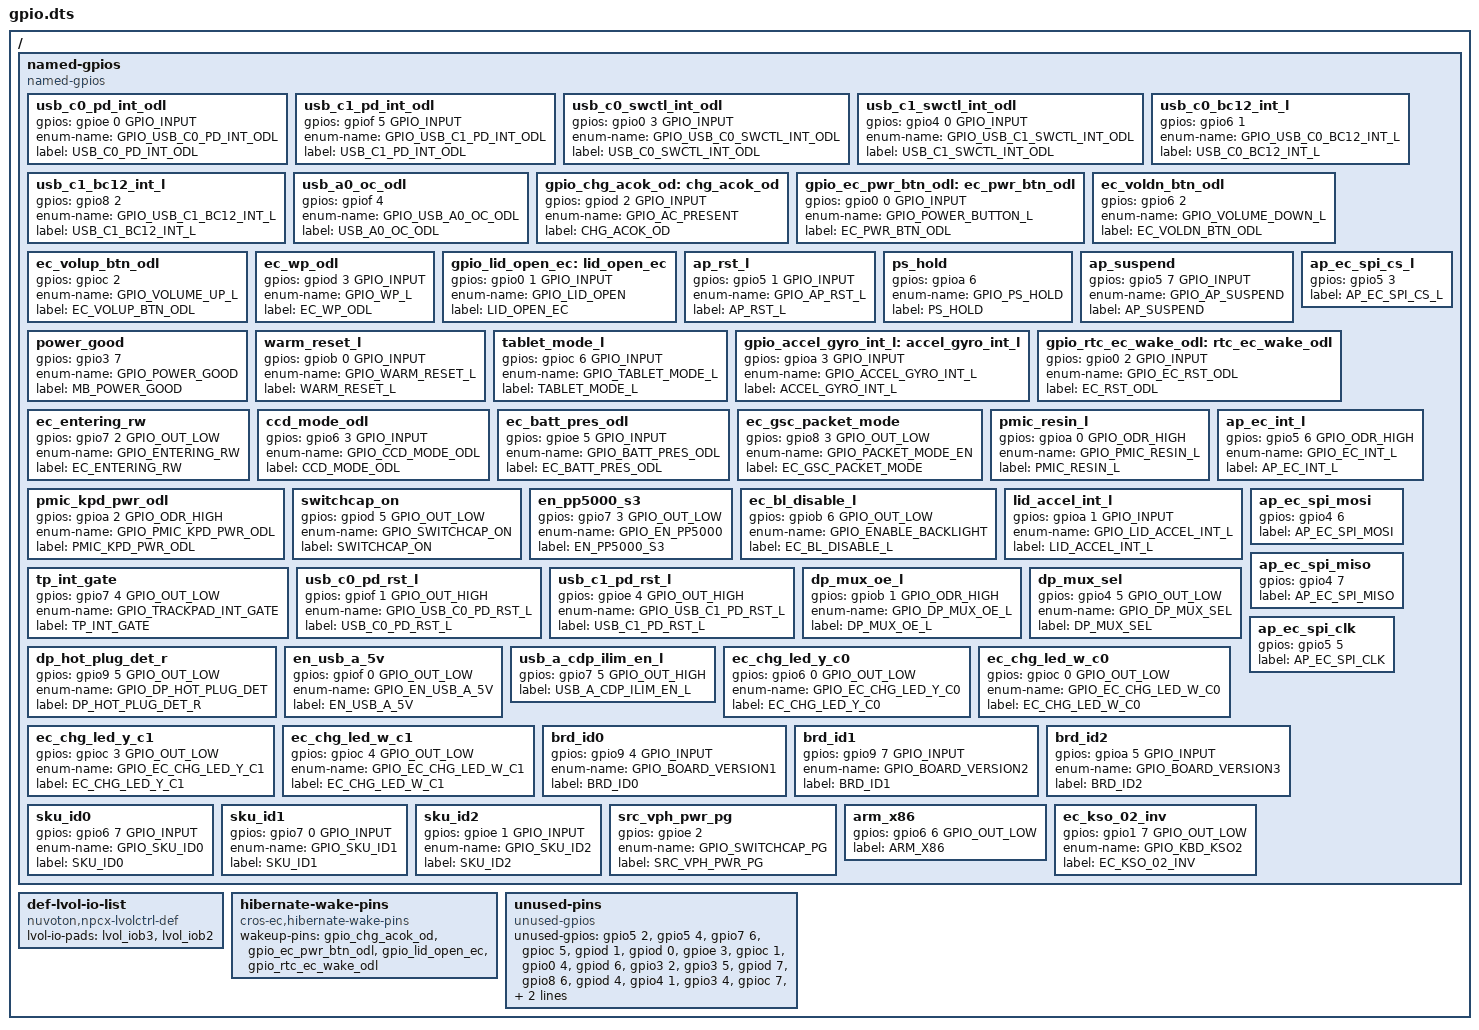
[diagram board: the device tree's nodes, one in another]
/* Copyright 2021 The Chromium OS Authors. All rights reserved.
 * Use of this source code is governed by a BSD-style license that can be
 * found in the LICENSE file.
 */

/ {
	named-gpios {
		compatible = "named-gpios";

		usb_c0_pd_int_odl {
			gpios = <&gpioe 0 GPIO_INPUT>;
			enum-name = "GPIO_USB_C0_PD_INT_ODL";
			label = "USB_C0_PD_INT_ODL";
		};
		usb_c1_pd_int_odl {
			gpios = <&gpiof 5 GPIO_INPUT>;
			enum-name = "GPIO_USB_C1_PD_INT_ODL";
			label = "USB_C1_PD_INT_ODL";
		};
		usb_c0_swctl_int_odl {
			gpios = <&gpio0 3 GPIO_INPUT>;
			enum-name = "GPIO_USB_C0_SWCTL_INT_ODL";
			label = "USB_C0_SWCTL_INT_ODL";
		};
		usb_c1_swctl_int_odl {
			gpios = <&gpio4 0 GPIO_INPUT>;
			enum-name = "GPIO_USB_C1_SWCTL_INT_ODL";
			label = "USB_C1_SWCTL_INT_ODL";
		};
		usb_c0_bc12_int_l {
			gpios = <&gpio6 1 (GPIO_INPUT | GPIO_PULL_UP)>;
			enum-name = "GPIO_USB_C0_BC12_INT_L";
			label = "USB_C0_BC12_INT_L";
		};
		usb_c1_bc12_int_l {
			gpios = <&gpio8 2 (GPIO_INPUT | GPIO_PULL_UP)>;
			enum-name = "GPIO_USB_C1_BC12_INT_L";
			label = "USB_C1_BC12_INT_L";
		};
		usb_a0_oc_odl {
			gpios = <&gpiof 4 (GPIO_INPUT | GPIO_PULL_UP)>;
			enum-name = "GPIO_USB_A0_OC_ODL";
			label = "USB_A0_OC_ODL";
		};
		gpio_chg_acok_od: chg_acok_od {
			gpios = <&gpiod 2 GPIO_INPUT>;
			enum-name = "GPIO_AC_PRESENT";
			label = "CHG_ACOK_OD";
		};
		gpio_ec_pwr_btn_odl: ec_pwr_btn_odl {
			gpios = <&gpio0 0 GPIO_INPUT>;
			enum-name = "GPIO_POWER_BUTTON_L";
			label = "EC_PWR_BTN_ODL";
		};
		ec_voldn_btn_odl {
			gpios = <&gpio6 2 (GPIO_INPUT | GPIO_PULL_UP)>;
			enum-name = "GPIO_VOLUME_DOWN_L";
			label = "EC_VOLDN_BTN_ODL";
		};
		ec_volup_btn_odl {
			gpios = <&gpioc 2 (GPIO_INPUT | GPIO_PULL_UP)>;
			enum-name = "GPIO_VOLUME_UP_L";
			label = "EC_VOLUP_BTN_ODL";
		};
		ec_wp_odl {
			gpios = <&gpiod 3 GPIO_INPUT>;
			enum-name = "GPIO_WP_L";
			label = "EC_WP_ODL";
		};
		gpio_lid_open_ec: lid_open_ec {
			gpios = <&gpio0 1 GPIO_INPUT>;
			enum-name = "GPIO_LID_OPEN";
			label = "LID_OPEN_EC";
		};
		ap_rst_l {
			gpios = <&gpio5 1 GPIO_INPUT>;
			enum-name = "GPIO_AP_RST_L";
			label = "AP_RST_L";
		};
		ps_hold {
			gpios = <&gpioa 6 (GPIO_INPUT | GPIO_PULL_DOWN)>;
			enum-name = "GPIO_PS_HOLD";
			label = "PS_HOLD";
		};
		ap_suspend {
			gpios = <&gpio5 7 GPIO_INPUT>;
			enum-name = "GPIO_AP_SUSPEND";
			label = "AP_SUSPEND";
		};
		power_good {
			gpios = <&gpio3 7 (GPIO_INPUT | GPIO_PULL_DOWN)>;
			enum-name = "GPIO_POWER_GOOD";
			label = "MB_POWER_GOOD";
		};
		warm_reset_l {
			gpios = <&gpiob 0 GPIO_INPUT>;
			enum-name = "GPIO_WARM_RESET_L";
			label = "WARM_RESET_L";
		};
		ap_ec_spi_cs_l {
			gpios = <&gpio5 3 (GPIO_INPUT | GPIO_PULL_DOWN)>;
			label = "AP_EC_SPI_CS_L";
		};
		tablet_mode_l {
			gpios = <&gpioc 6 GPIO_INPUT>;
			enum-name = "GPIO_TABLET_MODE_L";
			label = "TABLET_MODE_L";
		};
		gpio_accel_gyro_int_l: accel_gyro_int_l {
			gpios = <&gpioa 3 GPIO_INPUT>;
			enum-name = "GPIO_ACCEL_GYRO_INT_L";
			label = "ACCEL_GYRO_INT_L";
		};
		gpio_rtc_ec_wake_odl: rtc_ec_wake_odl {
			gpios = <&gpio0 2 GPIO_INPUT>;
			enum-name = "GPIO_EC_RST_ODL";
			label = "EC_RST_ODL";
		};
		ec_entering_rw {
			gpios = <&gpio7 2 GPIO_OUT_LOW>;
			enum-name = "GPIO_ENTERING_RW";
			label = "EC_ENTERING_RW";
		};
		ccd_mode_odl {
			gpios = <&gpio6 3 GPIO_INPUT>;
			enum-name = "GPIO_CCD_MODE_ODL";
			label = "CCD_MODE_ODL";
		};
		ec_batt_pres_odl {
			gpios = <&gpioe 5 GPIO_INPUT>;
			enum-name = "GPIO_BATT_PRES_ODL";
			label = "EC_BATT_PRES_ODL";
		};
		ec_gsc_packet_mode {
			gpios = <&gpio8 3 GPIO_OUT_LOW>;
			enum-name = "GPIO_PACKET_MODE_EN";
			label = "EC_GSC_PACKET_MODE";
		};
		pmic_resin_l {
			gpios = <&gpioa 0 GPIO_ODR_HIGH>;
			enum-name = "GPIO_PMIC_RESIN_L";
			label = "PMIC_RESIN_L";
		};
		pmic_kpd_pwr_odl {
			gpios = <&gpioa 2 GPIO_ODR_HIGH>;
			enum-name = "GPIO_PMIC_KPD_PWR_ODL";
			label = "PMIC_KPD_PWR_ODL";
		};
		ap_ec_int_l {
			gpios = <&gpio5 6 GPIO_ODR_HIGH>;
			enum-name = "GPIO_EC_INT_L";
			label = "AP_EC_INT_L";
		};
		switchcap_on {
			gpios = <&gpiod 5 GPIO_OUT_LOW>;
			enum-name = "GPIO_SWITCHCAP_ON";
			label = "SWITCHCAP_ON";
		};
		en_pp5000_s3 {
			gpios = <&gpio7 3 GPIO_OUT_LOW>;
			enum-name = "GPIO_EN_PP5000";
			label = "EN_PP5000_S3";
		};
		ec_bl_disable_l {
			gpios = <&gpiob 6 GPIO_OUT_LOW>;
			enum-name = "GPIO_ENABLE_BACKLIGHT";
			label = "EC_BL_DISABLE_L";
		};
		lid_accel_int_l {
			gpios = <&gpioa 1 GPIO_INPUT>;
			enum-name = "GPIO_LID_ACCEL_INT_L";
			label = "LID_ACCEL_INT_L";
		};
		tp_int_gate {
			gpios = <&gpio7 4 GPIO_OUT_LOW>;
			enum-name = "GPIO_TRACKPAD_INT_GATE";
			label = "TP_INT_GATE";
		};
		usb_c0_pd_rst_l {
			gpios = <&gpiof 1 GPIO_OUT_HIGH>;
			enum-name = "GPIO_USB_C0_PD_RST_L";
			label = "USB_C0_PD_RST_L";
		};
		usb_c1_pd_rst_l {
			gpios = <&gpioe 4 GPIO_OUT_HIGH>;
			enum-name = "GPIO_USB_C1_PD_RST_L";
			label = "USB_C1_PD_RST_L";
		};
		dp_mux_oe_l {
			gpios = <&gpiob 1 GPIO_ODR_HIGH>;
			enum-name = "GPIO_DP_MUX_OE_L";
			label = "DP_MUX_OE_L";
		};
		dp_mux_sel {
			gpios = <&gpio4 5 GPIO_OUT_LOW>;
			enum-name = "GPIO_DP_MUX_SEL";
			label = "DP_MUX_SEL";
		};
		dp_hot_plug_det_r {
			gpios = <&gpio9 5 GPIO_OUT_LOW>;
			enum-name = "GPIO_DP_HOT_PLUG_DET";
			label = "DP_HOT_PLUG_DET_R";
		};
		en_usb_a_5v {
			gpios = <&gpiof 0 GPIO_OUT_LOW>;
			enum-name = "GPIO_EN_USB_A_5V";
			label = "EN_USB_A_5V";
		};
		usb_a_cdp_ilim_en_l {
			gpios = <&gpio7 5 GPIO_OUT_HIGH>;
			label = "USB_A_CDP_ILIM_EN_L";
		};
		ec_chg_led_y_c0 {
			gpios = <&gpio6 0 GPIO_OUT_LOW>;
			enum-name = "GPIO_EC_CHG_LED_Y_C0";
			label = "EC_CHG_LED_Y_C0";
		};
		ec_chg_led_w_c0 {
			gpios = <&gpioc 0 GPIO_OUT_LOW>;
			enum-name = "GPIO_EC_CHG_LED_W_C0";
			label = "EC_CHG_LED_W_C0";
		};
		ec_chg_led_y_c1 {
			gpios = <&gpioc 3 GPIO_OUT_LOW>;
			enum-name = "GPIO_EC_CHG_LED_Y_C1";
			label = "EC_CHG_LED_Y_C1";
		};
		ec_chg_led_w_c1 {
			gpios = <&gpioc 4 GPIO_OUT_LOW>;
			enum-name = "GPIO_EC_CHG_LED_W_C1";
			label = "EC_CHG_LED_W_C1";
		};
		ap_ec_spi_mosi {
			gpios = <&gpio4 6 (GPIO_INPUT | GPIO_PULL_DOWN)>;
			label = "AP_EC_SPI_MOSI";
		};
		ap_ec_spi_miso {
			gpios = <&gpio4 7 (GPIO_INPUT | GPIO_PULL_DOWN)>;
			label = "AP_EC_SPI_MISO";
		};
		ap_ec_spi_clk {
			gpios = <&gpio5 5 (GPIO_INPUT | GPIO_PULL_DOWN)>;
			label = "AP_EC_SPI_CLK";
		};
		brd_id0 {
			gpios = <&gpio9 4 GPIO_INPUT>;
			enum-name = "GPIO_BOARD_VERSION1";
			label = "BRD_ID0";
		};
		brd_id1 {
			gpios = <&gpio9 7 GPIO_INPUT>;
			enum-name = "GPIO_BOARD_VERSION2";
			label = "BRD_ID1";
		};
		brd_id2 {
			gpios = <&gpioa 5 GPIO_INPUT>;
			enum-name = "GPIO_BOARD_VERSION3";
			label = "BRD_ID2";
		};
		sku_id0 {
			gpios = <&gpio6 7 GPIO_INPUT>;
			enum-name = "GPIO_SKU_ID0";
			label = "SKU_ID0";
		};
		sku_id1 {
			gpios = <&gpio7 0 GPIO_INPUT>;
			enum-name = "GPIO_SKU_ID1";
			label = "SKU_ID1";
		};
		sku_id2 {
			gpios = <&gpioe 1 GPIO_INPUT>;
			enum-name = "GPIO_SKU_ID2";
			label = "SKU_ID2";
		};
		src_vph_pwr_pg {
			gpios = <&gpioe 2 (GPIO_INPUT | GPIO_PULL_DOWN)>;
			enum-name = "GPIO_SWITCHCAP_PG";
			label = "SRC_VPH_PWR_PG";
		};
		arm_x86 {
			gpios = <&gpio6 6 GPIO_OUT_LOW>;
			label = "ARM_X86";
		};
		ec_kso_02_inv {
			gpios = <&gpio1 7 GPIO_OUT_LOW>;
			enum-name = "GPIO_KBD_KSO2";
			label = "EC_KSO_02_INV";
		};
	};

	def-lvol-io-list {
		compatible = "nuvoton,npcx-lvolctrl-def";
		lvol-io-pads = <
			&lvol_iob3 /* EC_I2C_SENSOR_SCL */
			&lvol_iob2 /* EC_I2C_SENSOR_SDA */
		>;
	};

	hibernate-wake-pins {
		compatible = "cros-ec,hibernate-wake-pins";
		wakeup-pins = <
			&gpio_chg_acok_od
			&gpio_ec_pwr_btn_odl
			&gpio_lid_open_ec
			&gpio_rtc_ec_wake_odl
		>;
	};

	unused-pins {
		compatible = "unused-gpios";
		unused-gpios =
			<&gpio5 2 0>,
			<&gpio5 4 0>,
			<&gpio7 6 0>,
			<&gpioc 5 0>,
			<&gpiod 1 0>,
			<&gpiod 0 0>,
			<&gpioe 3 0>,
			<&gpioc 1 0>,
			<&gpio0 4 0>,
			<&gpiod 6 0>,
			<&gpio3 2 0>,
			<&gpio3 5 0>,
			<&gpiod 7 0>,
			<&gpio8 6 0>,
			<&gpiod 4 0>,
			<&gpio4 1 0>,
			<&gpio3 4 0>,
			<&gpioc 7 0>,
			<&gpioa 4 0>,
			<&gpio9 6 0>,
			<&gpio9 3 0>,
			<&gpioa 7 0>,
			<&gpio5 0 0>,
			<&gpio8 1 0>;
	};
};
